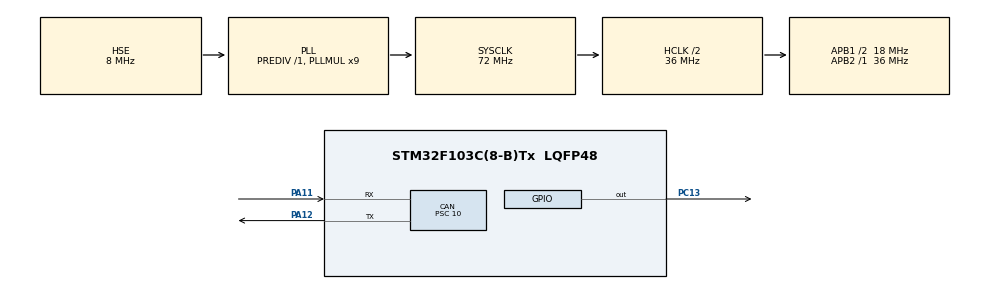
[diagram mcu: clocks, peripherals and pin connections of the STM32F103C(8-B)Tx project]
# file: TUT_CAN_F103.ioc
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CAN.BS1=CAN_BS1_10TQ
CAN.BS2=CAN_BS2_5TQ
CAN.CalculateBaudRate=112500
CAN.CalculateTimeBit=8888.88
CAN.CalculateTimeQuantum=555.5555555555555
CAN.Prescaler=10
Mcu.Family=STM32F1
Mcu.Name=STM32F103C(8-B)Tx
Mcu.Package=LQFP48
NVIC.CAN1_RX1_IRQn=true\:0\:0\:false\:false\:true\:true\:true
NVIC.PriorityGroup=NVIC_PRIORITYGROUP_4
PA11.Mode=CAN_Activate
PA11.Signal=CAN_RX
PA12.Mode=CAN_Activate
PA12.Signal=CAN_TX
PA13.Mode=Serial_Wire
PA13.Signal=SYS_JTMS-SWDIO
PA14.Mode=Serial_Wire
PA14.Signal=SYS_JTCK-SWCLK
PC13-TAMPER-RTC.Signal=GPIO_Output
PD0-OSC_IN.Mode=HSE-External-Oscillator
PD0-OSC_IN.Signal=RCC_OSC_IN
PD1-OSC_OUT.Mode=HSE-External-Oscillator
PD1-OSC_OUT.Signal=RCC_OSC_OUT
ProjectManager.HeapSize=0x200
ProjectManager.StackSize=0x400
ProjectManager.TargetToolchain=STM32CubeIDE
RCC.AHBCLKDivider=RCC_SYSCLK_DIV2
RCC.AHBFreq_Value=36000000
RCC.APB1CLKDivider=RCC_HCLK_DIV2
RCC.APB1Freq_Value=18000000
RCC.APB1TimFreq_Value=36000000
RCC.APB2Freq_Value=36000000
RCC.APB2TimFreq_Value=36000000
RCC.HCLKFreq_Value=36000000
RCC.PLLMUL=RCC_PLL_MUL9
RCC.PLLSourceVirtual=RCC_PLLSOURCE_HSE
RCC.SYSCLKFreq_VALUE=72000000
RCC.SYSCLKSource=RCC_SYSCLKSOURCE_PLLCLK
RCC.USBFreq_Value=72000000
board=custom

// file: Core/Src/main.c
/* USER CODE BEGIN Header */
/**
  ******************************************************************************
  * @file           : main.c
  * @brief          : Main program body
  ******************************************************************************
  * @attention
  *
  * <h2><center>&copy; Copyright (c) 2021 STMicroelectronics.
  * All rights reserved.</center></h2>
  *
  * This software component is licensed by ST under BSD 3-Clause license,
  * the "License"; You may not use this file except in compliance with the
  * License. You may obtain a copy of the License at:
  *                        opensource.org/licenses/BSD-3-Clause
  *
  ******************************************************************************
  */
/* USER CODE END Header */
#include "main.h"

CAN_HandleTypeDef hcan;

void SystemClock_Config(void);
static void MX_GPIO_Init(void);
static void MX_CAN_Init(void);

/* USER CODE BEGIN 0 */

CAN_TxHeaderTypeDef TxHeader;
CAN_RxHeaderTypeDef RxHeader;

uint8_t TxData[8];
uint8_t RxData[8];

uint32_t TxMailbox;

int datacheck = 0;

void HAL_CAN_RxFifo1MsgPendingCallback(CAN_HandleTypeDef *hcan) //Função para recebimento de mensagens via CAN
{
	HAL_CAN_GetRxMessage(hcan, CAN_RX_FIFO1, &RxHeader, RxData);
	if (RxHeader.DLC == 2)
	{
		datacheck = 1; // Variavel para indicar que uma mensagem foi recebida
	}
}

/* USER CODE END 0 */

int main(void)
{

  /* MCU Configuration--------------------------------------------------------*/

  /* Reset of all peripherals, Initializes the Flash interface and the Systick. */
  HAL_Init();

  /* Configure the system clock */
  SystemClock_Config();

  /* Initialize all configured peripherals */
  MX_GPIO_Init();
  MX_CAN_Init();
  /* USER CODE BEGIN 2 */

  HAL_CAN_Start(&hcan);

  // Activate the notification
  HAL_CAN_ActivateNotification(&hcan, CAN_IT_RX_FIFO1_MSG_PENDING);

  TxHeader.DLC = 2; // Quantidade de bytes para envio de mensagens maximo são 8 mas só foram necessarios 2
  TxHeader.IDE = CAN_ID_STD; // Indicação do tipo de ID neste caso ID Standarf
  TxHeader.RTR = CAN_RTR_DATA;
  TxHeader.StdId = 0x103;  // ID  do dispositivo

  /* USER CODE END 2 */

  /* Infinite loop */
  /* USER CODE BEGIN WHILE */
  while (1)
  {

	  TxData[0] = 200; // Delay a ser enviado em ms
	  TxData[1] = 20;  // Repetições para o loop do led do master

	  HAL_CAN_AddTxMessage(&hcan, &TxHeader, TxData, &TxMailbox);

    /* USER CODE END WHILE */

    /* USER CODE BEGIN 3 */

	  if (datacheck) // Função acionado ao receber uma mensagem
	  {
		  // blink the LED
		  for (int i=0; i<RxData[1]; i++) //Loop para acionamento do led indicando que esta recebendo comunicação
		  {
			  HAL_GPIO_TogglePin(GPIOC, GPIO_PIN_13); // Alternando o estado do LED
			  HAL_Delay(RxData[0]); // Delay de tempo
		  }

		  datacheck = 0; // Zerando a variavel de indicação

	  }
  }
  /* USER CODE END 3 */
}

void SystemClock_Config(void)
{
  RCC_OscInitTypeDef RCC_OscInitStruct = {0};
  RCC_ClkInitTypeDef RCC_ClkInitStruct = {0};

  /** Initializes the RCC Oscillators according to the specified parameters
  * in the RCC_OscInitTypeDef structure.
  */
  RCC_OscInitStruct.OscillatorType = RCC_OSCILLATORTYPE_HSE;
  RCC_OscInitStruct.HSEState = RCC_HSE_ON;
  RCC_OscInitStruct.HSEPredivValue = RCC_HSE_PREDIV_DIV1;
  RCC_OscInitStruct.HSIState = RCC_HSI_ON;
  RCC_OscInitStruct.PLL.PLLState = RCC_PLL_ON;
  RCC_OscInitStruct.PLL.PLLSource = RCC_PLLSOURCE_HSE;
  RCC_OscInitStruct.PLL.PLLMUL = RCC_PLL_MUL9;
  if (HAL_RCC_OscConfig(&RCC_OscInitStruct) != HAL_OK)
  {
    Error_Handler();
  }
  /** Initializes the CPU, AHB and APB buses clocks
  */
  RCC_ClkInitStruct.ClockType = RCC_CLOCKTYPE_HCLK|RCC_CLOCKTYPE_SYSCLK
                              |RCC_CLOCKTYPE_PCLK1|RCC_CLOCKTYPE_PCLK2;
  RCC_ClkInitStruct.SYSCLKSource = RCC_SYSCLKSOURCE_PLLCLK;
  RCC_ClkInitStruct.AHBCLKDivider = RCC_SYSCLK_DIV2;
  RCC_ClkInitStruct.APB1CLKDivider = RCC_HCLK_DIV2;
  RCC_ClkInitStruct.APB2CLKDivider = RCC_HCLK_DIV1;

  if (HAL_RCC_ClockConfig(&RCC_ClkInitStruct, FLASH_LATENCY_2) != HAL_OK)
  {
    Error_Handler();
  }
}

static void MX_CAN_Init(void)
{

  hcan.Instance = CAN1;
  hcan.Init.Prescaler = 10;
  hcan.Init.Mode = CAN_MODE_NORMAL;
  hcan.Init.SyncJumpWidth = CAN_SJW_1TQ;
  hcan.Init.TimeSeg1 = CAN_BS1_10TQ;
  hcan.Init.TimeSeg2 = CAN_BS2_5TQ;
  hcan.Init.TimeTriggeredMode = DISABLE;
  hcan.Init.AutoBusOff = DISABLE;
  hcan.Init.AutoWakeUp = DISABLE;
  hcan.Init.AutoRetransmission = DISABLE;
  hcan.Init.ReceiveFifoLocked = DISABLE;
  hcan.Init.TransmitFifoPriority = DISABLE;
  if (HAL_CAN_Init(&hcan) != HAL_OK)
  {
    Error_Handler();
  }
  /* USER CODE BEGIN CAN_Init 2 */

  CAN_FilterTypeDef canfilterconfig;

  canfilterconfig.FilterActivation = CAN_FILTER_ENABLE;
  canfilterconfig.FilterBank = 10;  // which filter bank to use from the assigned ones
  canfilterconfig.FilterFIFOAssignment = CAN_FILTER_FIFO1;
  canfilterconfig.FilterIdHigh = 0x102<<5;
  canfilterconfig.FilterIdLow = 0;
  canfilterconfig.FilterMaskIdHigh = 0x102<<5;
  canfilterconfig.FilterMaskIdLow = 0x0000;
  canfilterconfig.FilterMode = CAN_FILTERMODE_IDMASK;
  canfilterconfig.FilterScale = CAN_FILTERSCALE_32BIT;
  canfilterconfig.SlaveStartFilterBank = 0;  // doesn't matter in single can controllers

  HAL_CAN_ConfigFilter(&hcan, &canfilterconfig);

  /* USER CODE END CAN_Init 2 */

}

static void MX_GPIO_Init(void)
{
  GPIO_InitTypeDef GPIO_InitStruct = {0};

  /* GPIO Ports Clock Enable */
  __HAL_RCC_GPIOC_CLK_ENABLE();
  __HAL_RCC_GPIOD_CLK_ENABLE();
  __HAL_RCC_GPIOA_CLK_ENABLE();

  /*Configure GPIO pin Output Level */
  HAL_GPIO_WritePin(GPIOC, GPIO_PIN_13, GPIO_PIN_RESET);

  /*Configure GPIO pin : PC13 */
  GPIO_InitStruct.Pin = GPIO_PIN_13;
  GPIO_InitStruct.Mode = GPIO_MODE_OUTPUT_PP;
  GPIO_InitStruct.Pull = GPIO_NOPULL;
  GPIO_InitStruct.Speed = GPIO_SPEED_FREQ_LOW;
  HAL_GPIO_Init(GPIOC, &GPIO_InitStruct);

}

void Error_Handler(void)
{
  __disable_irq();
  while (1)
  {
  }
}

/************************ (C) COPYRIGHT STMicroelectronics *****END OF FILE****/
